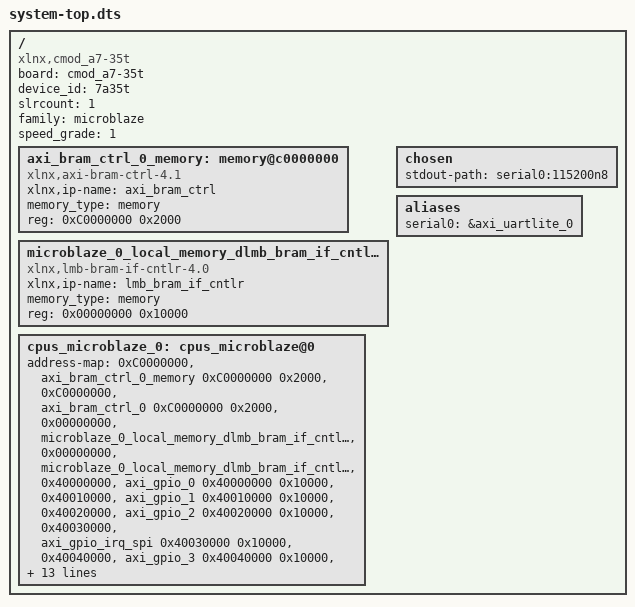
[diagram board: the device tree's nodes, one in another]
/dts-v1/;
#include "pl.dtsi"
/ {
	board = "cmod_a7-35t";
	compatible = "xlnx,cmod_a7-35t";
	device_id = "7a35t";
	#address-cells = <1>;
	#size-cells = <1>;
	slrcount = <1>;
	family = "microblaze";
	speed_grade = "1";
	axi_bram_ctrl_0_memory: memory@c0000000 {
		compatible = "xlnx,axi-bram-ctrl-4.1";
		xlnx,ip-name = "axi_bram_ctrl";
		device_type = "memory";
		memory_type = "memory";
		reg = <0xC0000000 0x2000>;
	};
	microblaze_0_local_memory_dlmb_bram_if_cntlr_memory: memory@0 {
		compatible = "xlnx,lmb-bram-if-cntlr-4.0";
		xlnx,ip-name = "lmb_bram_if_cntlr";
		device_type = "memory";
		memory_type = "memory";
		reg = <0x00000000 0x10000>;
	};
	chosen {
		stdout-path = "serial0:115200n8";
	};
	aliases {
		serial0 = &axi_uartlite_0;
	};
	cpus_microblaze_0: cpus_microblaze@0 {
		address-map = <0xC0000000 &axi_bram_ctrl_0_memory 0xC0000000 0x2000>, 
			      <0xC0000000 &axi_bram_ctrl_0 0xC0000000 0x2000>, 
			      <0x00000000 &microblaze_0_local_memory_dlmb_bram_if_cntlr_memory 0x00000000 0x10000>, 
			      <0x00000000 &microblaze_0_local_memory_dlmb_bram_if_cntlr 0x00000000 0x10000>, 
			      <0x40000000 &axi_gpio_0 0x40000000 0x10000>, 
			      <0x40010000 &axi_gpio_1 0x40010000 0x10000>, 
			      <0x40020000 &axi_gpio_2 0x40020000 0x10000>, 
			      <0x40030000 &axi_gpio_irq_spi 0x40030000 0x10000>, 
			      <0x40040000 &axi_gpio_3 0x40040000 0x10000>, 
			      <0x40050000 &axi_gpio_4 0x40050000 0x10000>, 
			      <0x40060000 &axi_gpio_5 0x40060000 0x10000>, 
			      <0x40070000 &axi_gpio_6 0x40070000 0x10000>, 
			      <0x40080000 &axi_gpio_7 0x40080000 0x10000>, 
			      <0x40090000 &axi_gpio_8 0x40090000 0x10000>, 
			      <0x400a0000 &axi_gpio_9 0x400a0000 0x10000>, 
			      <0x400b0000 &axi_gpio_10 0x400b0000 0x10000>, 
			      <0x40600000 &axi_uartlite_0 0x40600000 0x10000>, 
			      <0x41200000 &microblaze_0_axi_intc 0x41200000 0x10000>, 
			      <0x41e00000 &axi_dma_0 0x41e00000 0x10000>, 
			      <0x44a00000 &xadc_wiz_0 0x44a00000 0x10000>;
		#ranges-address-cells = <0x1>;
		#ranges-size-cells = <0x1>;
	};
};
